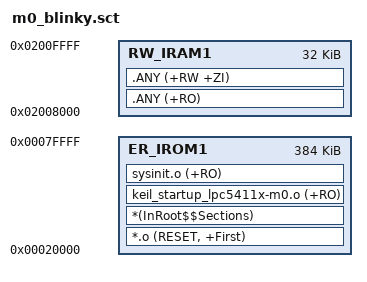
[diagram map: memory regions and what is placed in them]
; *************************************************************
; *** Scatter-Loading Description File generated by uVision ***
; *************************************************************

LR_IROM1 0x00020000 0x00060000  {    ; load region size_region
  ER_IROM1 0x00020000 0x00060000  {  ; load address = execution address
   *.o (RESET, +First)
   *(InRoot$$Sections)
   keil_startup_lpc5411x-m0.o (+RO)
   sysinit.o (+RO)
  }
  RW_IRAM1 0x02008000 0x00008000  {  ; RW data
   .ANY (+RO)
   .ANY (+RW +ZI)
  }
}


